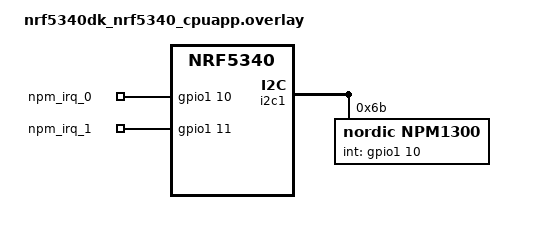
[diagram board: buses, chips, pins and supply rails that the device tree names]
/{
    /* Node with pin configuration for default state */
    buttons {
        compatible = "gpio-keys";
        npm_irq0: npm_irq_0 {
            gpios = <&gpio1 10 (GPIO_PULL_DOWN | GPIO_ACTIVE_HIGH)>;
            label = "npm_irq_0";
        };

        npm_irq1: npm_irq_1 {
            gpios = <&gpio1 11 (GPIO_PULL_DOWN | GPIO_ACTIVE_HIGH)>;
            label = "npm_irq_1";
        };
    };
};

&i2c1 {
    compatible = "nordic,nrf-twim";
    status = "okay";
    npmx: npm1300@6b {
        status = "okay";
		compatible = "nordic,npm1300";
		label = "npm1300";
		reg = <0x6b>;
		int-gpios = <&gpio1 10 (GPIO_PULL_DOWN | GPIO_ACTIVE_HIGH)>;
	};
};
